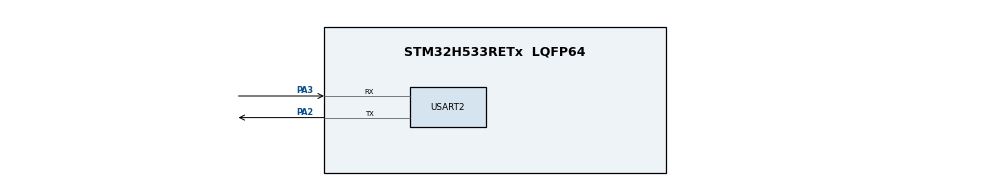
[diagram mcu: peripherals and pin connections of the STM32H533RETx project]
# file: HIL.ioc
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BOOTPATH.BootPathName=LEGACY
BOOTPATH.UserSelectedBootPath=LEGACY
CORTEX_M33_NS.Number-Cortex_Memory_Protection_Unit_Region0_OTP_RO_AREAS_Settings=MPU_REGION_NUMBER0
CORTEX_M33_NS.default_mode_Activation=1
CORTEX_M33_NS.userName=CORTEX_M33
Mcu.Family=STM32H5
Mcu.Name=STM32H533RETx
Mcu.Package=LQFP64
NVIC.PriorityGroup=NVIC_PRIORITYGROUP_4
PA13(JTMS/SWDIO).GPIO_Label=SWDIO
PA13(JTMS/SWDIO).Mode=Trace_Asynchronous_SW
PA13(JTMS/SWDIO).Signal=DEBUG_JTMS-SWDIO
PA14(JTCK/SWCLK).GPIO_Label=SWCLK
PA14(JTCK/SWCLK).Mode=Trace_Asynchronous_SW
PA14(JTCK/SWCLK).Signal=DEBUG_JTCK-SWCLK
PA2.Mode=Asynchronous
PA2.Signal=USART2_TX
PA3.Mode=Asynchronous
PA3.Signal=USART2_RX
PB3(JTDO/TRACESWO).GPIO_Label=SWO
PB3(JTDO/TRACESWO).Mode=Trace_Asynchronous_SW
PB3(JTDO/TRACESWO).Signal=DEBUG_JTDO-SWO
ProjectManager.HeapSize=0x200
ProjectManager.StackSize=0x400
ProjectManager.TargetToolchain=CMake
RCC.ADCFreq_Value=32000000
RCC.AHBFreq_Value=32000000
RCC.APB1Freq_Value=32000000
RCC.APB1TimFreq_Value=32000000
RCC.APB2Freq_Value=32000000
RCC.APB2TimFreq_Value=32000000
RCC.APB3Freq_Value=32000000
RCC.CSI_VALUE=4000000
RCC.CortexFreq_Value=32000000
RCC.EPOD_VALUE=4000000
RCC.HCLKFreq_Value=32000000
RCC.HSE_VALUE=25000000
RCC.HSI48_VALUE=48000000
RCC.HSI_VALUE=64000000
RCC.LSE_VALUE=32768
RCC.LSIRC_VALUE=32000
RCC.SYSCLKFreq_VALUE=32000000
RCC.USBFreq_Value=48000000
RCC.VCOOutputFreq_Value=516000000
USART2.VirtualMode-Asynchronous=VM_ASYNC
VP_BOOTPATH_VS_BOOTPATH.Mode=BP_Activate
VP_CORTEX_M33_NS_VS_Hclk.Mode=Hclk_Mode
VP_ICACHE_VS_ICACHE.Mode=DirectMappedCache
VP_MEMORYMAP_VS_MEMORYMAP.Mode=CurAppReg
VP_PWR_VS_LPOM.Mode=PowerOptimisation
VP_PWR_VS_SECSignals.Mode=Security/Privilege
board=NUCLEO-H533RE

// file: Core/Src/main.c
/* USER CODE BEGIN Header */
/**
  ******************************************************************************
  * @file           : main.c
  * @brief          : Main program body
  ******************************************************************************
  * @attention
  *
  * Copyright (c) 2026 STMicroelectronics.
  * All rights reserved.
  *
  * This software is licensed under terms that can be found in the LICENSE file
  * in the root directory of this software component.
  * If no LICENSE file comes with this software, it is provided AS-IS.
  *
  ******************************************************************************
  */
/* USER CODE END Header */
#include "main.h"
#include "icache.h"
#include "stm32h533xx.h"
#include "usart.h"
#include "gpio.h"
#include <stdio.h>
#include <sys/_intsup.h>

/* USER CODE BEGIN Includes */
#include "unity_fixture.h"
/* USER CODE END Includes */

void SystemClock_Config(void);
static void MPU_Config(void);

/* USER CODE BEGIN 0 */

void UART_PrintPolling(char *pData,int length)
{
	  for(uint8_t index = 0; index < length; index++)
	  {
		  while(!LL_USART_IsActiveFlag_TXE(USART2))
			  ;

		  LL_USART_TransmitData8(USART2, pData[index]);
	  }
}

int _write(int file, char *ptr, int len)
{
  /* Implement your write code here, this is used by puts and printf for example */
  // int i=0;
  // for(i=0 ; i<len ; i++)
  // {
  //     ITM_SendChar((*ptr++));
  // }
  UART_PrintPolling(ptr, len);
  return len;
}

static void RunAllTests(void)
{
    printf("\nRunning Scalar Profile tests...\n");
    RUN_TEST_GROUP(ScalarProfile);
}
/* USER CODE END 0 */

int main(void)
{

  /* MCU Configuration--------------------------------------------------------*/

  /* Reset of all peripherals, Initializes the Flash interface and the Systick. */

  /* MPU Configuration--------------------------------------------------------*/
  MPU_Config();

  /* System interrupt init*/
  NVIC_SetPriorityGrouping(NVIC_PRIORITYGROUP_4);

  /* SysTick_IRQn interrupt configuration */
  NVIC_SetPriority(SysTick_IRQn, NVIC_EncodePriority(NVIC_GetPriorityGrouping(),15, 0));

  /* Configure the system clock */
  SystemClock_Config();

  /* Initialize all configured peripherals */
  MX_GPIO_Init();
  MX_ICACHE_Init();
  MX_USART2_UART_Init();

  /* USER CODE BEGIN 2 */
    printf("\r\nBefore UnityMain\r\n");

const char *argv[] = {
    "test",
    "-v"
};

UnityMain(2, argv, RunAllTests);

    printf("\r\nAfter UnityMain\r\n");
  /* USER CODE END 2 */

  /* Infinite loop */
  while (1)
  {

  }
}

void SystemClock_Config(void)
{
  LL_FLASH_SetLatency(LL_FLASH_LATENCY_1);
  while(LL_FLASH_GetLatency()!= LL_FLASH_LATENCY_1)
  {
  }

  LL_PWR_SetRegulVoltageScaling(LL_PWR_REGU_VOLTAGE_SCALE3);
  while (LL_PWR_IsActiveFlag_VOS() == 0)
  {
  }
  LL_RCC_HSI_Enable();

   /* Wait till HSI is ready */
  while(LL_RCC_HSI_IsReady() != 1)
  {
  }

  LL_RCC_HSI_SetCalibTrimming(64);
  LL_RCC_HSI_SetDivider(LL_RCC_HSI_DIV_2);
  LL_RCC_SetSysClkSource(LL_RCC_SYS_CLKSOURCE_HSI);

   /* Wait till System clock is ready */
  while(LL_RCC_GetSysClkSource() != LL_RCC_SYS_CLKSOURCE_STATUS_HSI)
  {
  }

  LL_RCC_SetAHBPrescaler(LL_RCC_SYSCLK_DIV_1);
  LL_RCC_SetAPB1Prescaler(LL_RCC_APB1_DIV_1);
  LL_RCC_SetAPB2Prescaler(LL_RCC_APB2_DIV_1);
  LL_RCC_SetAPB3Prescaler(LL_RCC_APB3_DIV_1);

  LL_Init1msTick(32000000);

  LL_SetSystemCoreClock(32000000);
}

 /* MPU Configuration */

void MPU_Config(void)
{

  /* Disables the MPU */
  LL_MPU_Disable();

  /** Initializes and configures the Region 0 and the memory to be protected
  */
  LL_MPU_ConfigRegion(LL_MPU_REGION_NUMBER0, LL_MPU_REGION_ALL_RO|LL_MPU_INSTRUCTION_ACCESS_DISABLE|LL_MPU_ACCESS_NOT_SHAREABLE, LL_MPU_ATTRIBUTES_NUMBER0, 0x08FFF000, 0x08FFFFFF);
  LL_MPU_EnableRegion(LL_MPU_REGION_NUMBER0);

  /** Initializes and configures the Attribute 0 and the memory to be protected
  */
  LL_MPU_ConfigAttributes(LL_MPU_ATTRIBUTES_NUMBER0, LL_MPU_NOT_CACHEABLE);
  /* Enables the MPU */
  LL_MPU_Enable(LL_MPU_CTRL_PRIVILEGED_DEFAULT);

}

void Error_Handler(void)
{
  __disable_irq();
  while (1)
  {
  }
}
